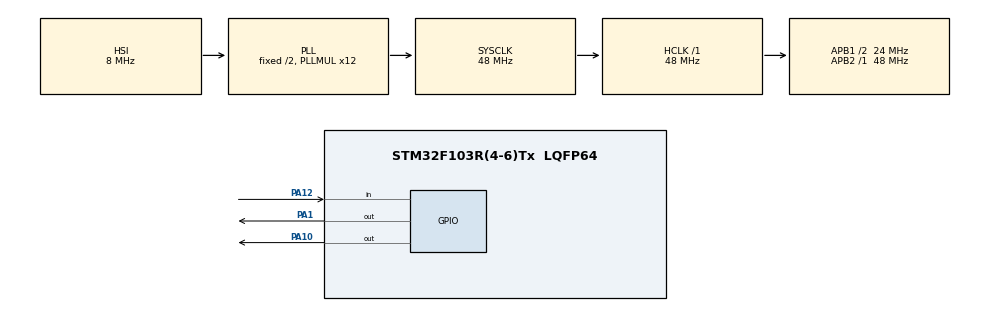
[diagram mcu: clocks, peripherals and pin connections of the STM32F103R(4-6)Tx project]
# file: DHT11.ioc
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Mcu.Family=STM32F1
Mcu.Name=STM32F103R(4-6)Tx
Mcu.Package=LQFP64
NVIC.PriorityGroup=NVIC_PRIORITYGROUP_4
PA1.Signal=GPIO_Output
PA10.PinState=GPIO_PIN_SET
PA10.Signal=GPIO_Output
PA12.GPIO_PuPd=GPIO_PULLUP
PA12.Signal=GPIO_Input
PA13.Mode=Serial_Wire
PA13.Signal=SYS_JTMS-SWDIO
PA14.Mode=Serial_Wire
PA14.Signal=SYS_JTCK-SWCLK
PD0-OSC_IN.Mode=HSE-External-Oscillator
PD0-OSC_IN.Signal=RCC_OSC_IN
PD1-OSC_OUT.Mode=HSE-External-Oscillator
PD1-OSC_OUT.Signal=RCC_OSC_OUT
ProjectManager.HeapSize=0x200
ProjectManager.StackSize=0x400
ProjectManager.TargetToolchain=MDK-ARM V5.27
RCC.AHBFreq_Value=48000000
RCC.APB1CLKDivider=RCC_HCLK_DIV2
RCC.APB1Freq_Value=24000000
RCC.APB1TimFreq_Value=48000000
RCC.APB2Freq_Value=48000000
RCC.APB2TimFreq_Value=48000000
RCC.HCLKFreq_Value=48000000
RCC.HSEDivPLL=RCC_HSE_PREDIV_DIV2
RCC.PLLMUL=RCC_PLL_MUL12
RCC.SYSCLKFreq_VALUE=48000000
RCC.SYSCLKSource=RCC_SYSCLKSOURCE_PLLCLK
RCC.USBFreq_Value=48000000
TIM1.Period=0xffff-1
TIM1.Prescaler=48-1
VP_TIM1_VS_ClockSourceINT.Mode=Internal
board=custom

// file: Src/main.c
/* USER CODE BEGIN Header */
/**
  ******************************************************************************
  * @file           : main.c
  * @brief          : Main program body
  ******************************************************************************
  * @attention
  *
  * <h2><center>&copy; Copyright (c) 2020 STMicroelectronics.
  * All rights reserved.</center></h2>
  *
  * This software component is licensed by ST under BSD 3-Clause license,
  * the "License"; You may not use this file except in compliance with the
  * License. You may obtain a copy of the License at:
  *                        opensource.org/licenses/BSD-3-Clause
  *
  ******************************************************************************
  */
/* USER CODE END Header */

#include "main.h"

TIM_HandleTypeDef htim1;

/* USER CODE BEGIN PV */
 uint8_t temp1,temp2,R1,R2,paraty;
 uint8_t i,j;
 uint8_t buff[5];
 uint16_t counter;
/* USER CODE END PV */

void SystemClock_Config(void);
static void MX_GPIO_Init(void);
static void MX_TIM1_Init(void);

/* USER CODE BEGIN 0 */
//void Set_Pin_Output (GPIO_TypeDef *GPIOx, uint16_t GPIO_Pin)
//{
//	GPIO_InitTypeDef GPIO_InitStruct = {0};
//	GPIO_InitStruct.Pin = GPIO_Pin;
//	GPIO_InitStruct.Mode = GPIO_MODE_OUTPUT_PP;
//	GPIO_InitStruct.Speed = GPIO_SPEED_FREQ_LOW;
//	HAL_GPIO_Init(GPIOx, &GPIO_InitStruct);
//}

//void Set_Pin_Input (GPIO_TypeDef *GPIOx, uint16_t GPIO_Pin)
//{
//	GPIO_InitTypeDef GPIO_InitStruct = {0};
//	GPIO_InitStruct.Pin = GPIO_Pin;
//	GPIO_InitStruct.Mode = GPIO_MODE_INPUT;
//	GPIO_InitStruct.Pull = GPIO_NOPULL;
//	HAL_GPIO_Init(GPIOx, &GPIO_InitStruct);
//}
//uint16_t delay (uint16_t time)
//	{
//			__HAL_TIM_SET_COUNTER(&htim1,0);
//			while(__HAL_TIM_GET_COUNTER(&htim1)<time);
//		}
//	void DHT11_Start()
//{
//	HAL_GPIO_WritePin(GPIOB, GPIO_PIN_12, 0);
//	delay(18000);
//	HAL_GPIO_WritePin(GPIOB, GPIO_PIN_12, 1);
//	delay(20);
//}
//uint8_t DHT11_check()
// {
//	 uint8_t response = 0;
//	 delay(40);
//	 if(!HAL_GPIO_ReadPin(GPIOA,GPIO_PIN_12))
//	 {
//		 delay(80);
//		 if(!HAL_GPIO_ReadPin(GPIOA,GPIO_PIN_12)) response=1;
//		 else response=-1;
//	 }
//	 while (HAL_GPIO_ReadPin(GPIOA,GPIO_PIN_12));
//	 return response;
// }
//
//uint8_t DHT11_Read ()
// {
//	 uint8_t i,j;
//	 for(j=0;j<8;j++)
//	 {
//		 delay(40);
//		 if(!HAL_GPIO_ReadPin(GPIOA,GPIO_PIN_12))
//		  i&= ~(1<<(7-j));
//		 else i|= (1<<(7-j));
//		 while (HAL_GPIO_ReadPin(GPIOA,GPIO_PIN_12));
//	 }
// }

/* USER CODE END 0 */

int main(void)
{

  /* MCU Configuration--------------------------------------------------------*/

  /* Reset of all peripherals, Initializes the Flash interface and the Systick. */
  HAL_Init();

  /* Configure the system clock */
  SystemClock_Config();

  /* Initialize all configured peripherals */
  MX_GPIO_Init();
  MX_TIM1_Init();
  /* USER CODE BEGIN 2 */
  HAL_TIM_Base_Start(&htim1);
  HAL_GPIO_WritePin(GPIOB, GPIO_PIN_12, 1);
  /* USER CODE END 2 */

  /* Infinite loop */
  /* USER CODE BEGIN WHILE */
  while (1)
  {
		 	 HAL_GPIO_WritePin(GPIOB, GPIO_PIN_12,0);
	  HAL_Delay(18);
	  HAL_GPIO_WritePin(GPIOB, GPIO_PIN_12, 1);
	  __HAL_TIM_SET_COUNTER(&htim1,0);
	  //if(HAL_GPIO_ReadPin(GPIOB, GPIO_PIN_12))
	  while(__HAL_TIM_GET_COUNTER(&htim1)<10)
	  {
		  if(HAL_GPIO_ReadPin(GPIOB, GPIO_PIN_12)) {

		  break;}
	  }
	  counter= __HAL_TIM_GET_COUNTER(&htim1);
	  if(counter>=10)
	  {
		  while(1)
		  {

		  }
	  }

	  __HAL_TIM_SET_COUNTER(&htim1,0);
	  while(__HAL_TIM_GET_COUNTER(&htim1)<45)
	  	  {
	  		  if(!HAL_GPIO_ReadPin(GPIOB, GPIO_PIN_12)) {break;}
	  	  }
	  	  counter= __HAL_TIM_GET_COUNTER(&htim1);
	  	  if(counter>=45||counter<=5)
	  	  {
	  		  while(1)
	  		  {
	  			 //HAL_GPIO_TogglePin(GPIOE, GPIO_PIN_10);
	  				  //HAL_GPIO_WritePin(GPIOE, GPIO_PIN_10,RESET);
	  				 // HAL_Delay(100);
	  		  }
	  	  }
// cho chan PB12  len cao
			  __HAL_TIM_SET_COUNTER(&htim1,0);
				  while(__HAL_TIM_GET_COUNTER(&htim1)<90)
				  {
					  if(HAL_GPIO_ReadPin(GPIOB, GPIO_PIN_12)) break;
				  }

				  if(__HAL_TIM_GET_COUNTER(&htim1)>=90||__HAL_TIM_GET_COUNTER(&htim1)<=70)
				  {
					  while(1)
					  {

					  }
				  }
  // cho chan PB12  xuong thap
			  __HAL_TIM_SET_COUNTER(&htim1,0);
				  while(__HAL_TIM_GET_COUNTER(&htim1)<95)
				  {
					  if(!HAL_GPIO_ReadPin(GPIOB, GPIO_PIN_12)) break;
				  }
				  if(__HAL_TIM_GET_COUNTER(&htim1)>=95||__HAL_TIM_GET_COUNTER(&htim1)<=75)
				  {
					  while(1)
					  {

					  }
				  }
			// nhan byte so1
				  for(i=0;i<8;i++)
				  {
						// cho chan PB12  len cao
						__HAL_TIM_SET_COUNTER(&htim1,0);
						while(__HAL_TIM_GET_COUNTER(&htim1)<65)
							{
							if(HAL_GPIO_ReadPin(GPIOB, GPIO_PIN_12)) break;
							}
						if(__HAL_TIM_GET_COUNTER(&htim1)>=65||__HAL_TIM_GET_COUNTER(&htim1)<=45)
							{
								while(1)
								{

								}
							}
						// cho chan PB12  xuong thap
						__HAL_TIM_SET_COUNTER(&htim1,0);
						while(__HAL_TIM_GET_COUNTER(&htim1)<80)
							{
							 if(!HAL_GPIO_ReadPin(GPIOB, GPIO_PIN_12)) break;
							}
						if(__HAL_TIM_GET_COUNTER(&htim1)>=80||__HAL_TIM_GET_COUNTER(&htim1)<=10)
							{
								while(1)
								{

								}
							}
						buff[i] <<=1;
						if(counter>45)
						  {
							buff[i] |=1;
						  }
						else
						  {
							buff[i] &=~1;
						  }

				  }

					  HAL_GPIO_TogglePin(GPIOA, GPIO_PIN_10);
					  	  //HAL_GPIO_WritePin(GPIOE, GPIO_PIN_10,RESET);
					  	  HAL_Delay(100);

    /* USER CODE END WHILE */

  }
}

void SystemClock_Config(void)
{
  RCC_OscInitTypeDef RCC_OscInitStruct = {0};
  RCC_ClkInitTypeDef RCC_ClkInitStruct = {0};

  /** Initializes the CPU, AHB and APB busses clocks
  */
  RCC_OscInitStruct.OscillatorType = RCC_OSCILLATORTYPE_HSI;
  RCC_OscInitStruct.HSIState = RCC_HSI_ON;
  RCC_OscInitStruct.HSICalibrationValue = RCC_HSICALIBRATION_DEFAULT;
  RCC_OscInitStruct.PLL.PLLState = RCC_PLL_ON;
  RCC_OscInitStruct.PLL.PLLSource = RCC_PLLSOURCE_HSI_DIV2;
  RCC_OscInitStruct.PLL.PLLMUL = RCC_PLL_MUL12;
  if (HAL_RCC_OscConfig(&RCC_OscInitStruct) != HAL_OK)
  {
    Error_Handler();
  }
  /** Initializes the CPU, AHB and APB busses clocks
  */
  RCC_ClkInitStruct.ClockType = RCC_CLOCKTYPE_HCLK|RCC_CLOCKTYPE_SYSCLK
                              |RCC_CLOCKTYPE_PCLK1|RCC_CLOCKTYPE_PCLK2;
  RCC_ClkInitStruct.SYSCLKSource = RCC_SYSCLKSOURCE_PLLCLK;
  RCC_ClkInitStruct.AHBCLKDivider = RCC_SYSCLK_DIV1;
  RCC_ClkInitStruct.APB1CLKDivider = RCC_HCLK_DIV2;
  RCC_ClkInitStruct.APB2CLKDivider = RCC_HCLK_DIV1;

  if (HAL_RCC_ClockConfig(&RCC_ClkInitStruct, FLASH_LATENCY_1) != HAL_OK)
  {
    Error_Handler();
  }
}

static void MX_TIM1_Init(void)
{

  TIM_ClockConfigTypeDef sClockSourceConfig = {0};
  TIM_MasterConfigTypeDef sMasterConfig = {0};

  htim1.Instance = TIM1;
  htim1.Init.Prescaler = 48-1;
  htim1.Init.CounterMode = TIM_COUNTERMODE_UP;
  htim1.Init.Period = 0xffff-1;
  htim1.Init.ClockDivision = TIM_CLOCKDIVISION_DIV1;
  htim1.Init.RepetitionCounter = 0;
  htim1.Init.AutoReloadPreload = TIM_AUTORELOAD_PRELOAD_DISABLE;
  if (HAL_TIM_Base_Init(&htim1) != HAL_OK)
  {
    Error_Handler();
  }
  sClockSourceConfig.ClockSource = TIM_CLOCKSOURCE_INTERNAL;
  if (HAL_TIM_ConfigClockSource(&htim1, &sClockSourceConfig) != HAL_OK)
  {
    Error_Handler();
  }
  sMasterConfig.MasterOutputTrigger = TIM_TRGO_RESET;
  sMasterConfig.MasterSlaveMode = TIM_MASTERSLAVEMODE_DISABLE;
  if (HAL_TIMEx_MasterConfigSynchronization(&htim1, &sMasterConfig) != HAL_OK)
  {
    Error_Handler();
  }

}

static void MX_GPIO_Init(void)
{
  GPIO_InitTypeDef GPIO_InitStruct = {0};

  /* GPIO Ports Clock Enable */
  __HAL_RCC_GPIOD_CLK_ENABLE();
  __HAL_RCC_GPIOA_CLK_ENABLE();

  /*Configure GPIO pin Output Level */
  HAL_GPIO_WritePin(GPIOA, GPIO_PIN_1, GPIO_PIN_RESET);

  /*Configure GPIO pin Output Level */
  HAL_GPIO_WritePin(GPIOA, GPIO_PIN_10, GPIO_PIN_SET);

  /*Configure GPIO pins : PA1 PA10 */
  GPIO_InitStruct.Pin = GPIO_PIN_1|GPIO_PIN_10;
  GPIO_InitStruct.Mode = GPIO_MODE_OUTPUT_PP;
  GPIO_InitStruct.Pull = GPIO_NOPULL;
  GPIO_InitStruct.Speed = GPIO_SPEED_FREQ_LOW;
  HAL_GPIO_Init(GPIOA, &GPIO_InitStruct);

  /*Configure GPIO pin : PA12 */
  GPIO_InitStruct.Pin = GPIO_PIN_12;
  GPIO_InitStruct.Mode = GPIO_MODE_INPUT;
  GPIO_InitStruct.Pull = GPIO_PULLUP;
  HAL_GPIO_Init(GPIOA, &GPIO_InitStruct);

}

void Error_Handler(void)
{
}

/************************ (C) COPYRIGHT STMicroelectronics *****END OF FILE****/
